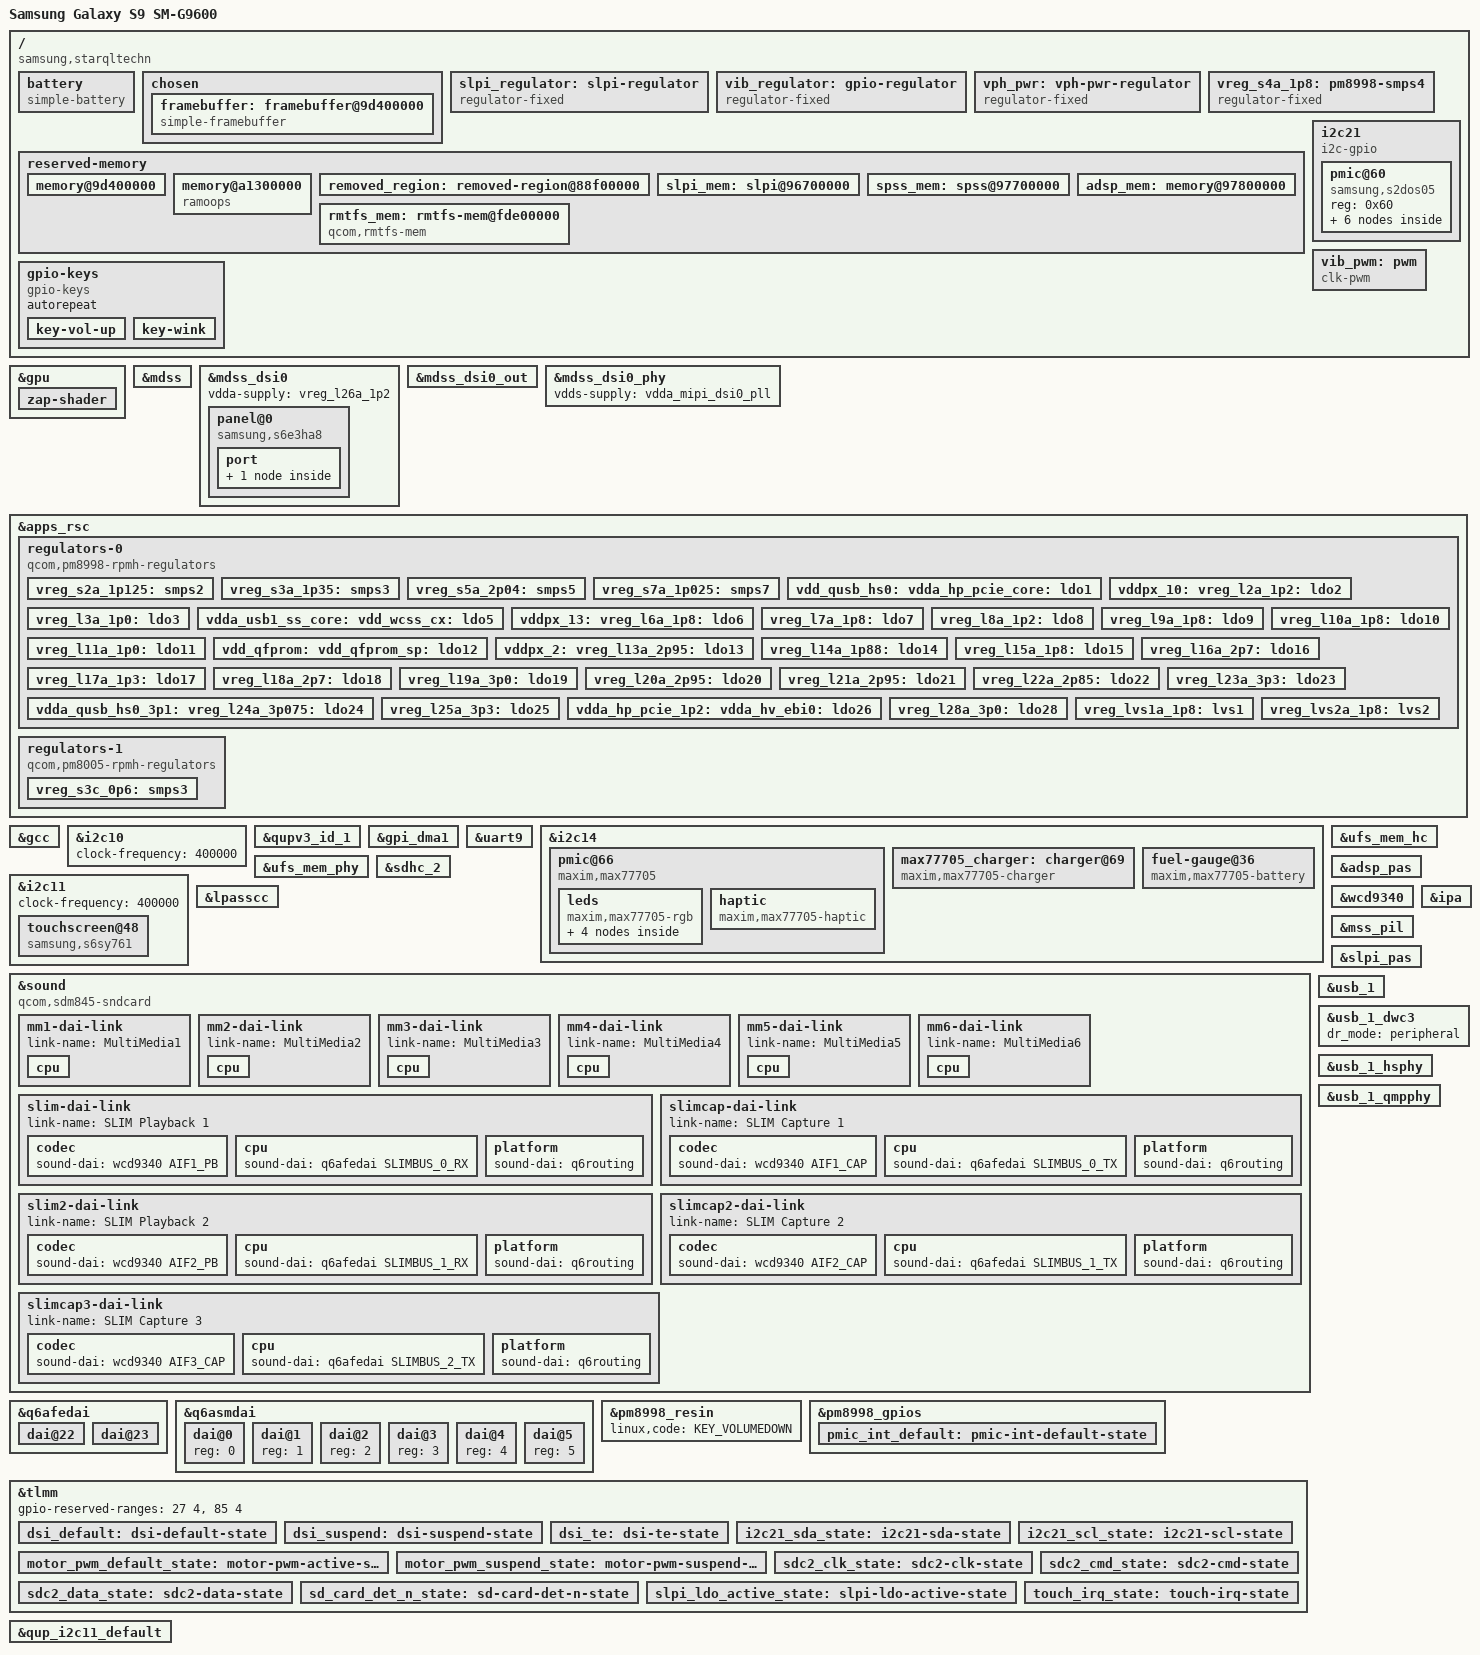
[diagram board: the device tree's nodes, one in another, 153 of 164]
// SPDX-License-Identifier: GPL-2.0
/*
 * SDM845 Samsung S9 (SM-G9600) (starqltechn / star2qltechn) common device tree source
 *
 * Copyright (c) 2020, The Linux Foundation. All rights reserved.
 */

/dts-v1/;

#include <dt-bindings/input/linux-event-codes.h>
#include <dt-bindings/gpio/gpio.h>
#include <dt-bindings/leds/common.h>
#include <dt-bindings/regulator/qcom,rpmh-regulator.h>
#include <dt-bindings/sound/qcom,q6afe.h>
#include <dt-bindings/sound/qcom,q6asm.h>
#include <dt-bindings/sound/qcom,wcd934x.h>

#include "sdm845.dtsi"
#include "pm8998.dtsi"
#include "sdm845-wcd9340.dtsi"

/delete-node/ &rmtfs_mem;
/delete-node/ &spss_mem;
/delete-node/ &adsp_mem;
/delete-node/ &slpi_mem;

/ {
	chassis-type = "handset";
	model = "Samsung Galaxy S9 SM-G9600";
	compatible = "samsung,starqltechn", "qcom,sdm845";

	battery: battery {
		compatible = "simple-battery";
		constant-charge-current-max-microamp = <2150000>;
		charge-full-design-microamp-hours = <3000000>;

		over-voltage-threshold-microvolt = <4500000>;
		voltage-min-design-microvolt = <3400000>;
		voltage-max-design-microvolt = <4350000>;
	};

	chosen {
		#address-cells = <2>;
		#size-cells = <2>;
		ranges;
		framebuffer: framebuffer@9d400000 {
			compatible = "simple-framebuffer";
			reg = <0 0x9d400000 0 (2960 * 1440 * 4)>;//2400000
			width = <1440>;
			height = <2960>;
			stride = <(1440 * 4)>;
			format = "a8r8g8b8";
			vci-supply = <&s2dos05_ldo4>;
			vddr-supply = <&s2dos05_buck>;
			vdd3-supply = <&s2dos05_ldo1>;
		};
	};

	slpi_regulator: slpi-regulator {
		compatible = "regulator-fixed";
		pinctrl-0 = <&slpi_ldo_active_state>;
		pinctrl-names = "default";

		regulator-always-on;
		regulator-boot-on;
		regulator-min-microvolt = <1800000>;
		regulator-max-microvolt = <1800000>;
		regulator-name = "slpi";

		enable-active-high;
		gpio = <&tlmm 8 GPIO_ACTIVE_HIGH>;
	};

	vib_regulator: gpio-regulator {
		compatible = "regulator-fixed";

		regulator-name = "haptic";
		regulator-min-microvolt = <1800000>;
		regulator-max-microvolt = <1800000>;

		gpio = <&pm8998_gpios 18 GPIO_ACTIVE_HIGH>;
		enable-active-high;

		regulator-boot-on;
	};

	vph_pwr: vph-pwr-regulator {
		compatible = "regulator-fixed";
		regulator-name = "vph_pwr";
		regulator-min-microvolt = <3700000>;
		regulator-max-microvolt = <3700000>;
	};

	/*
	 * Apparently RPMh does not provide support for PM8998 S4 because it
	 * is always-on; model it as a fixed regulator.
	 */
	vreg_s4a_1p8: pm8998-smps4 {
		compatible = "regulator-fixed";
		regulator-name = "vreg_s4a_1p8";

		regulator-min-microvolt = <1800000>;
		regulator-max-microvolt = <1800000>;

		regulator-always-on;
		regulator-boot-on;

		vin-supply = <&vph_pwr>;
	};

	reserved-memory {
		memory@9d400000 {
			reg = <0x0 0x9d400000 0x0 0x02400000>;
			no-map;
		};

		memory@a1300000 {
			compatible = "ramoops";
			reg = <0x0 0xa1300000 0x0 0x100000>;
			record-size = <0x40000>;
			console-size = <0x40000>;
			ftrace-size = <0x40000>;
			pmsg-size = <0x40000>;
		};

		/*
		 * It seems like reserving the old rmtfs_mem region is also needed to prevent
		 * random crashes which are most likely modem related, more testing needed.
		 */
		removed_region: removed-region@88f00000 {
			reg = <0 0x88f00000 0 0x1c00000>;
			no-map;
		};

		slpi_mem: slpi@96700000 {
			reg = <0 0x96700000 0 0x1000000>;
			no-map;
		};

		spss_mem: spss@97700000 {
			reg = <0 0x97700000 0 0x100000>;
			no-map;
		};

		adsp_mem: memory@97800000 {
			reg = <0 0x97800000 0 0x2000000>;
			no-map;
		};

		rmtfs_mem: rmtfs-mem@fde00000 {
			compatible = "qcom,rmtfs-mem";
			reg = <0 0xfde00000 0 0x202000>;
			qcom,use-guard-pages;
			no-map;

			qcom,client-id = <1>;
			qcom,vmid = <QCOM_SCM_VMID_MSS_MSA>;
		};
	};

	i2c21 {
		compatible = "i2c-gpio";
		sda-gpios = <&tlmm 127 (GPIO_ACTIVE_HIGH | GPIO_OPEN_DRAIN)>;
		scl-gpios = <&tlmm 128 (GPIO_ACTIVE_HIGH | GPIO_OPEN_DRAIN)>;
		i2c-gpio,delay-us = <2>;
		pinctrl-0 = <&i2c21_sda_state &i2c21_scl_state>;
		pinctrl-names = "default";
		#address-cells = <1>;
		#size-cells = <0>;

		pmic@60 {
			compatible = "samsung,s2dos05";
			reg = <0x60>;

			regulators {
				s2dos05_ldo1: ldo1 {
					regulator-active-discharge = <1>;
					regulator-enable-ramp-delay = <12000>;
					regulator-min-microvolt = <1500000>;
					regulator-max-microvolt = <2000000>;
					regulator-name = "ldo1";
				};

				s2dos05_ldo2: ldo2 {
					regulator-active-discharge = <1>;
					regulator-boot-on;
					regulator-enable-ramp-delay = <12000>;
					regulator-min-microvolt = <1800000>;
					regulator-max-microvolt = <1800000>;
					regulator-name = "ldo2";
				};

				s2dos05_ldo3: ldo3 {
					regulator-active-discharge = <1>;
					regulator-boot-on;
					regulator-enable-ramp-delay = <12000>;
					regulator-min-microvolt = <3000000>;
					regulator-max-microvolt = <3000000>;
					regulator-name = "ldo3";
				};

				s2dos05_ldo4: ldo4 {
					regulator-active-discharge = <1>;
					regulator-enable-ramp-delay = <12000>;
					regulator-min-microvolt = <2700000>;
					regulator-max-microvolt = <3775000>;
					regulator-name = "ldo4";
				};

				s2dos05_buck: buck {
					regulator-active-discharge = <1>;
					regulator-enable-ramp-delay = <12000>;
					regulator-min-microvolt = <850000>;
					regulator-max-microvolt = <2100000>;
					regulator-name = "buck";
				};
			};
		};
	};

	gpio-keys {
		compatible = "gpio-keys";
		autorepeat;

		key-vol-up {
			label = "Volume Up";
			gpios = <&pm8998_gpios 6 GPIO_ACTIVE_LOW>;
			linux,code = <KEY_VOLUMEUP>;
			debounce-interval = <15>;
		};

		key-wink {
			label = "Bixby";
			gpios = <&pm8998_gpios 19 GPIO_ACTIVE_LOW>;
			linux,code = <KEY_ENTER>;
			debounce-interval = <15>;
		};
	};

	vib_pwm: pwm {
		compatible = "clk-pwm";
		#pwm-cells = <2>;
		assigned-clock-parents = <&rpmhcc RPMH_CXO_CLK>;
		assigned-clocks = <&gcc GCC_GP1_CLK_SRC>;
		clocks = <&gcc GCC_GP1_CLK>;
		pinctrl-0 = <&motor_pwm_default_state>;
		pinctrl-1 = <&motor_pwm_suspend_state>;
		pinctrl-names = "default", "suspend";
	};
};

&gpu {
	status = "okay";

	zap-shader {
		memory-region = <&gpu_mem>;
		firmware-name = "qcom/sdm845/starqltechn/a630_zap.mbn";
	};
};

&mdss {
	status = "okay";
};

&mdss_dsi0 {
	vdda-supply = <&vreg_l26a_1p2>;
	status = "okay";

	panel@0 {
		compatible = "samsung,s6e3ha8";
		reg = <0>;
		vci-supply = <&s2dos05_ldo4>;
		vddr-supply = <&s2dos05_buck>;
		vdd3-supply = <&s2dos05_ldo1>;
		te-gpios = <&tlmm 10 GPIO_ACTIVE_HIGH>;
		reset-gpios = <&tlmm 6 GPIO_ACTIVE_HIGH>;
		pinctrl-0 = <&dsi_default &dsi_te>;
		pinctrl-1 = <&dsi_suspend &dsi_te>;
		pinctrl-names = "default", "suspend";

		port {
			panel_in: endpoint {
				remote-endpoint = <&mdss_dsi0_out>;
			};
		};
	};
};

&mdss_dsi0_out {
	data-lanes = <0 1 2 3>;
	remote-endpoint = <&panel_in>;
};

&mdss_dsi0_phy {
	vdds-supply = <&vdda_mipi_dsi0_pll>;
	status = "okay";
};

&apps_rsc {
	regulators-0 {
		compatible = "qcom,pm8998-rpmh-regulators";
		qcom,pmic-id = "a";

		vdd-s1-supply = <&vph_pwr>;
		vdd-s2-supply = <&vph_pwr>;
		vdd-s3-supply = <&vph_pwr>;
		vdd-s4-supply = <&vph_pwr>;
		vdd-s5-supply = <&vph_pwr>;
		vdd-s6-supply = <&vph_pwr>;
		vdd-s7-supply = <&vph_pwr>;
		vdd-s8-supply = <&vph_pwr>;
		vdd-s9-supply = <&vph_pwr>;
		vdd-s10-supply = <&vph_pwr>;
		vdd-s11-supply = <&vph_pwr>;
		vdd-s12-supply = <&vph_pwr>;
		vdd-s13-supply = <&vph_pwr>;
		vdd-l1-l27-supply = <&vreg_s7a_1p025>;
		vdd-l2-l8-l17-supply = <&vreg_s3a_1p35>;
		vdd-l3-l11-supply = <&vreg_s7a_1p025>;
		vdd-l4-l5-supply = <&vreg_s7a_1p025>;
		vdd-l6-supply = <&vph_pwr>;
		vdd-l7-l12-l14-l15-supply = <&vreg_s5a_2p04>;
		vdd-l26-supply = <&vreg_s3a_1p35>;
		vin-lvs-1-2-supply = <&vreg_s4a_1p8>;

		vreg_s2a_1p125: smps2 {
			regulator-min-microvolt = <1100000>;
			regulator-max-microvolt = <1100000>;
		};

		vreg_s3a_1p35: smps3 {
			regulator-min-microvolt = <1352000>;
			regulator-max-microvolt = <1352000>;
		};

		vreg_s5a_2p04: smps5 {
			regulator-min-microvolt = <1904000>;
			regulator-max-microvolt = <2040000>;
		};

		vreg_s7a_1p025: smps7 {
			regulator-min-microvolt = <900000>;
			regulator-max-microvolt = <1028000>;
		};

		vdd_qusb_hs0:
		vdda_hp_pcie_core:
		vdda_mipi_csi0_0p9:
		vdda_mipi_csi1_0p9:
		vdda_mipi_csi2_0p9:
		vdda_mipi_dsi0_pll:
		vdda_mipi_dsi1_pll:
		vdda_qlink_lv:
		vdda_qlink_lv_ck:
		vdda_qrefs_0p875:
		vdda_pcie_core:
		vdda_pll_cc_ebi01:
		vdda_pll_cc_ebi23:
		vdda_sp_sensor:
		vdda_ufs1_core:
		vdda_ufs2_core:
		vreg_l1a_0p875: ldo1 {
			regulator-min-microvolt = <880000>;
			regulator-max-microvolt = <880000>;
			regulator-initial-mode = <RPMH_REGULATOR_MODE_HPM>;
		};

		vddpx_10:
		vreg_l2a_1p2: ldo2 {
			regulator-min-microvolt = <1200000>;
			regulator-max-microvolt = <1200000>;
			regulator-initial-mode = <RPMH_REGULATOR_MODE_HPM>;
			regulator-always-on;
		};

		vreg_l3a_1p0: ldo3 {
			regulator-min-microvolt = <1000000>;
			regulator-max-microvolt = <1000000>;
			regulator-initial-mode = <RPMH_REGULATOR_MODE_HPM>;
		};

		vdda_usb1_ss_core:
		vdd_wcss_cx:
		vdd_wcss_mx:
		vdda_wcss_pll:
		vreg_l5a_0p8: ldo5 {
			regulator-min-microvolt = <800000>;
			regulator-max-microvolt = <800000>;
			regulator-initial-mode = <RPMH_REGULATOR_MODE_HPM>;
		};

		vddpx_13:
		vreg_l6a_1p8: ldo6 {
			regulator-min-microvolt = <1856000>;
			regulator-max-microvolt = <1856000>;
			regulator-initial-mode = <RPMH_REGULATOR_MODE_HPM>;
		};

		vreg_l7a_1p8: ldo7 {
			regulator-min-microvolt = <1800000>;
			regulator-max-microvolt = <1800000>;
			regulator-initial-mode = <RPMH_REGULATOR_MODE_HPM>;
		};

		vreg_l8a_1p2: ldo8 {
			regulator-min-microvolt = <1200000>;
			regulator-max-microvolt = <1248000>;
			regulator-initial-mode = <RPMH_REGULATOR_MODE_HPM>;
		};

		vreg_l9a_1p8: ldo9 {
			regulator-min-microvolt = <1704000>;
			regulator-max-microvolt = <2928000>;
			regulator-initial-mode = <RPMH_REGULATOR_MODE_HPM>;
		};

		vreg_l10a_1p8: ldo10 {
			regulator-min-microvolt = <1704000>;
			regulator-max-microvolt = <2928000>;
			regulator-initial-mode = <RPMH_REGULATOR_MODE_HPM>;
		};

		vreg_l11a_1p0: ldo11 {
			regulator-min-microvolt = <1000000>;
			regulator-max-microvolt = <1048000>;
			regulator-initial-mode = <RPMH_REGULATOR_MODE_HPM>;
		};

		vdd_qfprom:
		vdd_qfprom_sp:
		vdda_apc1_cs_1p8:
		vdda_gfx_cs_1p8:
		vdda_qrefs_1p8:
		vdda_qusb_hs0_1p8:
		vddpx_11:
		vreg_l12a_1p8: ldo12 {
			regulator-min-microvolt = <1800000>;
			regulator-max-microvolt = <1800000>;
			regulator-initial-mode = <RPMH_REGULATOR_MODE_HPM>;
		};

		vddpx_2:
		vreg_l13a_2p95: ldo13 {
			regulator-min-microvolt = <1800000>;
			regulator-max-microvolt = <2960000>;
			regulator-initial-mode = <RPMH_REGULATOR_MODE_HPM>;
		};

		vreg_l14a_1p88: ldo14 {
			regulator-min-microvolt = <1800000>;
			regulator-max-microvolt = <1800000>;
			regulator-initial-mode = <RPMH_REGULATOR_MODE_HPM>;
		};

		vreg_l15a_1p8: ldo15 {
			regulator-min-microvolt = <1800000>;
			regulator-max-microvolt = <1800000>;
			regulator-initial-mode = <RPMH_REGULATOR_MODE_HPM>;
		};

		vreg_l16a_2p7: ldo16 {
			regulator-min-microvolt = <2704000>;
			regulator-max-microvolt = <2704000>;
			regulator-initial-mode = <RPMH_REGULATOR_MODE_HPM>;
		};

		vreg_l17a_1p3: ldo17 {
			regulator-min-microvolt = <1304000>;
			regulator-max-microvolt = <1304000>;
			regulator-initial-mode = <RPMH_REGULATOR_MODE_HPM>;
		};

		vreg_l18a_2p7: ldo18 {
			regulator-min-microvolt = <2704000>;
			regulator-max-microvolt = <2960000>;
			regulator-initial-mode = <RPMH_REGULATOR_MODE_HPM>;
		};

		vreg_l19a_3p0: ldo19 {
			regulator-min-microvolt = <2856000>;
			regulator-max-microvolt = <3104000>;
			regulator-initial-mode = <RPMH_REGULATOR_MODE_HPM>;
		};

		vreg_l20a_2p95: ldo20 {
			regulator-min-microvolt = <2704000>;
			regulator-max-microvolt = <2960000>;
			regulator-initial-mode = <RPMH_REGULATOR_MODE_HPM>;
		};

		vreg_l21a_2p95: ldo21 {
			regulator-min-microvolt = <2704000>;
			regulator-max-microvolt = <2960000>;
			regulator-initial-mode = <RPMH_REGULATOR_MODE_HPM>;
		};

		vreg_l22a_2p85: ldo22 {
			regulator-min-microvolt = <2864000>;
			regulator-max-microvolt = <3312000>;
			regulator-initial-mode = <RPMH_REGULATOR_MODE_HPM>;
		};

		vreg_l23a_3p3: ldo23 {
			regulator-min-microvolt = <3000000>;
			regulator-max-microvolt = <3312000>;
			regulator-initial-mode = <RPMH_REGULATOR_MODE_HPM>;
		};

		vdda_qusb_hs0_3p1:
		vreg_l24a_3p075: ldo24 {
			regulator-min-microvolt = <3088000>;
			regulator-max-microvolt = <3088000>;
			regulator-initial-mode = <RPMH_REGULATOR_MODE_HPM>;
		};

		vreg_l25a_3p3: ldo25 {
			regulator-min-microvolt = <3300000>;
			regulator-max-microvolt = <3312000>;
			regulator-initial-mode = <RPMH_REGULATOR_MODE_HPM>;
		};

		vdda_hp_pcie_1p2:
		vdda_hv_ebi0:
		vdda_hv_ebi1:
		vdda_hv_ebi2:
		vdda_hv_ebi3:
		vdda_mipi_csi_1p25:
		vdda_mipi_dsi0_1p2:
		vdda_mipi_dsi1_1p2:
		vdda_pcie_1p2:
		vdda_ufs1_1p2:
		vdda_ufs2_1p2:
		vdda_usb1_ss_1p2:
		vdda_usb2_ss_1p2:
		vreg_l26a_1p2: ldo26 {
			regulator-min-microvolt = <1200000>;
			regulator-max-microvolt = <1200000>;
			regulator-initial-mode = <RPMH_REGULATOR_MODE_HPM>;
		};

		vreg_l28a_3p0: ldo28 {
			regulator-min-microvolt = <2856000>;
			regulator-max-microvolt = <3008000>;
			regulator-initial-mode = <RPMH_REGULATOR_MODE_HPM>;
		};

		vreg_lvs1a_1p8: lvs1 {
			regulator-min-microvolt = <1800000>;
			regulator-max-microvolt = <1800000>;
		};

		vreg_lvs2a_1p8: lvs2 {
			regulator-min-microvolt = <1800000>;
			regulator-max-microvolt = <1800000>;
		};
	};

	regulators-1 {
		compatible = "qcom,pm8005-rpmh-regulators";
		qcom,pmic-id = "c";

		vdd-s1-supply = <&vph_pwr>;
		vdd-s2-supply = <&vph_pwr>;
		vdd-s3-supply = <&vph_pwr>;
		vdd-s4-supply = <&vph_pwr>;

		vreg_s3c_0p6: smps3 {
			regulator-min-microvolt = <600000>;
			regulator-max-microvolt = <600000>;
		};
	};
};

&gcc {
	protected-clocks = <GCC_QSPI_CORE_CLK>,
				<GCC_QSPI_CORE_CLK_SRC>,
				<GCC_QSPI_CNOC_PERIPH_AHB_CLK>,
				<GCC_LPASS_Q6_AXI_CLK>,
				<GCC_LPASS_SWAY_CLK>;
};

&i2c10 {
	clock-frequency = <400000>;
	status = "okay";
};

&qupv3_id_1 {
	status = "okay";
};

&gpi_dma1 {
	status = "okay";
};

&uart9 {
	status = "okay";
};

&i2c14 {
	status = "okay";

	pmic@66 {
		compatible = "maxim,max77705";
		reg = <0x66>;
		interrupt-parent = <&pm8998_gpios>;
		interrupts = <11 IRQ_TYPE_LEVEL_LOW>;
		pinctrl-0 = <&pmic_int_default>;
		pinctrl-names = "default";
		#address-cells = <1>;
		#size-cells = <0>;

		leds {
			compatible = "maxim,max77705-rgb";

			multi-led {
				color = <LED_COLOR_ID_RGB>;
				function = LED_FUNCTION_STATUS;
				#address-cells = <1>;
				#size-cells = <0>;

				led@1 {
					reg = <1>;
					color = <LED_COLOR_ID_RED>;
				};

				led@2 {
					reg = <2>;
					color = <LED_COLOR_ID_GREEN>;
				};

				led@3 {
					reg = <3>;
					color = <LED_COLOR_ID_BLUE>;
				};
			};
		};

		haptic {
			compatible = "maxim,max77705-haptic";
			haptic-supply = <&vib_regulator>;
			pwms = <&vib_pwm 0 52084>;
		};
	};

	max77705_charger: charger@69 {
		reg = <0x69>;
		compatible = "maxim,max77705-charger";
		monitored-battery = <&battery>;
		interrupt-parent = <&pm8998_gpios>;
		interrupts = <11 IRQ_TYPE_LEVEL_LOW>;
	};

	fuel-gauge@36 {
		reg = <0x36>;
		compatible = "maxim,max77705-battery";
		power-supplies = <&max77705_charger>;
		maxim,rsns-microohm = <5000>;
		interrupt-parent = <&pm8998_gpios>;
		interrupts = <11 IRQ_TYPE_LEVEL_LOW>;
	};
};

&ufs_mem_hc {
	reset-gpios = <&tlmm 150 GPIO_ACTIVE_LOW>;
	vcc-supply = <&vreg_l20a_2p95>;
	vcc-max-microamp = <600000>;
	status = "okay";
};

&ufs_mem_phy {
	vdda-phy-supply = <&vdda_ufs1_core>;
	vdda-pll-supply = <&vdda_ufs1_1p2>;
	status = "okay";
};

&sdhc_2 {
	pinctrl-0 = <&sdc2_clk_state &sdc2_cmd_state &sdc2_data_state &sd_card_det_n_state>;
	pinctrl-names = "default";
	cd-gpios = <&tlmm 126 GPIO_ACTIVE_LOW>;
	vmmc-supply = <&vreg_l21a_2p95>;
	vqmmc-supply = <&vddpx_2>;
	status = "okay";
};

&i2c11 {
	clock-frequency = <400000>;
	status = "okay";

	touchscreen@48 {
		compatible = "samsung,s6sy761";
		reg = <0x48>;
		interrupt-parent = <&tlmm>;
		interrupts = <120 IRQ_TYPE_LEVEL_HIGH>;
		vdd-supply = <&s2dos05_ldo2>;
		avdd-supply = <&s2dos05_ldo3>;

		pinctrl-0 = <&touch_irq_state>;
		pinctrl-names = "default";
	};
};

&adsp_pas {
	firmware-name = "qcom/sdm845/starqltechn/adsp.mbn";
	status = "okay";
};

&lpasscc {
	status = "okay";
};

&sound {
	compatible = "qcom,sdm845-sndcard";
	model = "Samsung Galaxy S9";
	pinctrl-0 = <&quat_mi2s_active &quat_mi2s_sd0_active &quat_mi2s_sd1_active>;
	pinctrl-names = "default";
	status = "okay";

	audio-routing = "RX_BIAS", "MCLK",
			"AMIC2", "MIC BIAS2",	/* Headset Mic */
			"AMIC3", "MIC BIAS2",	/* FM radio left Tx */
			"AMIC4", "MIC BIAS2",	/* FM radio right Tx */
			"DMIC0", "MCLK",	/* Bottom Mic */
			"DMIC0", "MIC BIAS1",
			"DMIC2", "MCLK",	/* Top Mic */
			"DMIC2", "MIC BIAS3";

	mm1-dai-link {
		link-name = "MultiMedia1";

		cpu {
			sound-dai = <&q6asmdai MSM_FRONTEND_DAI_MULTIMEDIA1>;
		};
	};

	mm2-dai-link {
		link-name = "MultiMedia2";

		cpu {
			sound-dai = <&q6asmdai MSM_FRONTEND_DAI_MULTIMEDIA2>;
		};
	};

	mm3-dai-link {
		link-name = "MultiMedia3";

		cpu {
			sound-dai = <&q6asmdai MSM_FRONTEND_DAI_MULTIMEDIA3>;
		};
	};

	mm4-dai-link {
		link-name = "MultiMedia4";

		cpu {
			sound-dai = <&q6asmdai MSM_FRONTEND_DAI_MULTIMEDIA4>;
		};
	};

	mm5-dai-link {
		link-name = "MultiMedia5";

		cpu {
			sound-dai = <&q6asmdai MSM_FRONTEND_DAI_MULTIMEDIA5>;
		};
	};

	mm6-dai-link {
		link-name = "MultiMedia6";

		cpu {
			sound-dai = <&q6asmdai MSM_FRONTEND_DAI_MULTIMEDIA6>;
		};
	};

	slim-dai-link {
		link-name = "SLIM Playback 1";

		codec {
			sound-dai = <&wcd9340 AIF1_PB>;
		};

		cpu {
			sound-dai = <&q6afedai SLIMBUS_0_RX>;
		};

		platform {
			sound-dai = <&q6routing>;
		};
	};

	slimcap-dai-link {
		link-name = "SLIM Capture 1";

		codec {
			sound-dai = <&wcd9340 AIF1_CAP>;
		};

		cpu {
			sound-dai = <&q6afedai SLIMBUS_0_TX>;
		};

		platform {
			sound-dai = <&q6routing>;
		};
	};

	slim2-dai-link {
		link-name = "SLIM Playback 2";

		codec {
			sound-dai = <&wcd9340 AIF2_PB>;
		};

		cpu {
			sound-dai = <&q6afedai SLIMBUS_1_RX>;
		};

		platform {
			sound-dai = <&q6routing>;
		};
	};

	slimcap2-dai-link {
		link-name = "SLIM Capture 2";

		codec {
			sound-dai = <&wcd9340 AIF2_CAP>;
		};

		cpu {
			sound-dai = <&q6afedai SLIMBUS_1_TX>;
		};

		platform {
			sound-dai = <&q6routing>;
		};
	};

	slimcap3-dai-link {
		link-name = "SLIM Capture 3";

		codec {
			sound-dai = <&wcd9340 AIF3_CAP>;
		};

		cpu {
			sound-dai = <&q6afedai SLIMBUS_2_TX>;
		};

		platform {
			sound-dai = <&q6routing>;
		};
	};
};

&q6afedai {
	dai@22 {
		reg = <22>;
		qcom,sd-lines = <1>;
	};

	dai@23 {
		reg = <23>;
		qcom,sd-lines = <0>;
	};
};

&q6asmdai {
	dai@0 {
		reg = <0>;
	};

	dai@1 {
		reg = <1>;
	};

	dai@2 {
		reg = <2>;
	};

	dai@3 {
		reg = <3>;
	};

	dai@4 {
		reg = <4>;
	};

	dai@5 {
		reg = <5>;
	};
};

&wcd9340 {
	reset-gpios = <&tlmm 64 GPIO_ACTIVE_HIGH>;
	vdd-buck-supply = <&vreg_s4a_1p8>;
	vdd-buck-sido-supply = <&vreg_s4a_1p8>;
	vdd-tx-supply = <&vreg_s4a_1p8>;
	vdd-rx-supply = <&vreg_s4a_1p8>;
	vdd-io-supply = <&vreg_s4a_1p8>;
	qcom,micbias1-microvolt = <1800000>;
	qcom,micbias2-microvolt = <2700000>;
	qcom,micbias3-microvolt = <1800000>;
	qcom,micbias4-microvolt = <1800000>;
};

&mss_pil {
	firmware-name = "qcom/sdm845/starqltechn/mba.mbn",
			"qcom/sdm845/starqltechn/modem.mbn";
	status = "okay";
};

&ipa {
	qcom,gsi-loader = "self";
	memory-region = <&ipa_fw_mem>;
	firmware-name = "qcom/sdm845/starqltechn/ipa_fws.mbn";
	status = "okay";
};

&slpi_pas {
	firmware-name = "qcom/sdm845/starqltechn/slpi.mbn";
	cx-supply = <&slpi_regulator>;

	status = "okay";
};

&usb_1 {
	status = "okay";
};

&usb_1_dwc3 {
	/* Until we have Type C hooked up we'll force this as peripheral. */
	dr_mode = "peripheral";
};

&usb_1_hsphy {
	vdd-supply = <&vdda_usb1_ss_core>;
	vdda-pll-supply = <&vdda_qusb_hs0_1p8>;
	vdda-phy-dpdm-supply = <&vdda_qusb_hs0_3p1>;

	qcom,imp-res-offset-value = <8>;
	qcom,hstx-trim-value = <QUSB2_V2_HSTX_TRIM_21_6_MA>;
	qcom,preemphasis-level = <QUSB2_V2_PREEMPHASIS_5_PERCENT>;
	qcom,preemphasis-width = <QUSB2_V2_PREEMPHASIS_WIDTH_HALF_BIT>;
	status = "okay";
};

&usb_1_qmpphy {
	vdda-phy-supply = <&vdda_usb1_ss_1p2>;
	vdda-pll-supply = <&vdda_usb1_ss_core>;
	status = "okay";
};

&pm8998_resin {
	linux,code = <KEY_VOLUMEDOWN>;
	status = "okay";
};

&pm8998_gpios {
	pmic_int_default: pmic-int-default-state {
		pins = "gpio11";
		function = "normal";
		input-enable;
		bias-disable;
		power-source = <0>;
	};
};

&tlmm {
	gpio-reserved-ranges = <27 4>, /* SPI (eSE - embedded Secure Element) */
			       <85 4>; /* SPI (fingerprint reader) */

	dsi_default: dsi-default-state {
		pins = "gpio6";
		function = "gpio";
		drive-strength = <8>;
		bias-disable;
	};

	dsi_suspend: dsi-suspend-state {
		pins = "gpio6";
		function = "gpio";
		drive-strength = <2>;
		bias-pull-down;
	};

	dsi_te: dsi-te-state {
		pins = "gpio10";
		function = "mdp_vsync";
		drive-strength = <2>;
		bias-pull-down;
	};

	i2c21_sda_state: i2c21-sda-state {
		pins = "gpio127";
		function = "gpio";
		drive-strength = <2>;
		bias-disable;
	};

	i2c21_scl_state: i2c21-scl-state {
		pins = "gpio128";
		function = "gpio";
		drive-strength = <2>;
		bias-disable;
	};

	motor_pwm_default_state: motor-pwm-active-state {
		pins = "gpio57";
		function = "gcc_gp1";
		drive-strength = <2>;
		bias-disable;
		output-high;
	};

	motor_pwm_suspend_state: motor-pwm-suspend-state {
		pins = "gpio57";
		function = "gpio";
		drive-strength = <2>;
		bias-disable;
		output-low;
	};

	sdc2_clk_state: sdc2-clk-state {
		pins = "sdc2_clk";
		bias-disable;

		/*
		 * It seems that mmc_test reports errors if drive
		 * strength is not 16 on clk, cmd, and data pins.
		 */
		drive-strength = <16>;
	};

	sdc2_cmd_state: sdc2-cmd-state {
		pins = "sdc2_cmd";
		bias-pull-up;
		drive-strength = <16>;
	};

	sdc2_data_state: sdc2-data-state {
		pins = "sdc2_data";
		bias-pull-up;
		drive-strength = <16>;
	};

	sd_card_det_n_state: sd-card-det-n-state {
		pins = "gpio126";
		function = "gpio";
		bias-pull-up;
	};

	slpi_ldo_active_state: slpi-ldo-active-state {
		pins = "gpio8";
		function = "gpio";
		drive-strength = <2>;
		bias-disable;
	};

	touch_irq_state: touch-irq-state {
		pins = "gpio120";
		function = "gpio";
		bias-disable;
	};
};

&qup_i2c11_default {
	drive-strength = <2>;
	bias-disable;
};
